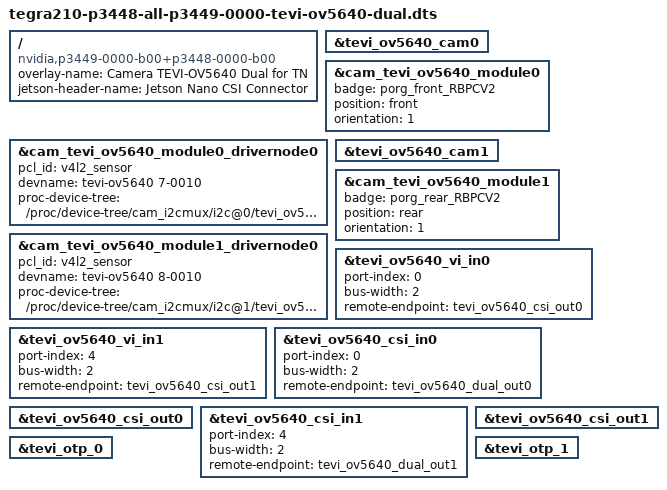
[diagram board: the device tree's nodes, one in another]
// SPDX-License-Identifier: GPL-2.0-only
/*
 * Jetson Device-tree overlay for Camera IMX477 rbpcv3 for t210 single
 * cam connector baseboards
 *
 * Copyright (c) 2021 NVIDIA CORPORATION. All rights reserved.
 *
 */

/dts-v1/;
/plugin/;

/ {
	overlay-name = "Camera TEVI-OV5640 Dual for TN";
	jetson-header-name = "Jetson Nano CSI Connector";
	compatible = "nvidia,p3449-0000-b00+p3448-0000-b00", "nvidia,p3449-0000-b00+p3448-0002-b00";

	/* TEVI-OV5640 dual sensor module */
	fragment@0 {
		target = <&tevi_ov5640_cam0>;
		__overlay__ {
			status = "okay";
		};
	};
	fragment@1 {
		target = <&cam_tevi_ov5640_module0>;
		__overlay__ {
			status = "okay";
			badge = "porg_front_RBPCV2";
			position = "front";
			orientation = "1";
		};
	};
	fragment@2 {
		target = <&cam_tevi_ov5640_module0_drivernode0>;
		__overlay__ {
			status = "okay";
			pcl_id = "v4l2_sensor";
			devname = "tevi-ov5640 7-0010";
			proc-device-tree = "/proc/device-tree/cam_i2cmux/i2c@0/tevi_ov5640_a@3d";
		};
	};
	fragment@3 {
		target = <&tevi_ov5640_cam1>;
		__overlay__ {
			status = "okay";
		};
	};
	fragment@4 {
		target = <&cam_tevi_ov5640_module1>;
		__overlay__ {
			status = "okay";
			badge = "porg_rear_RBPCV2";
			position = "rear";
			orientation = "1";
		};
	};
	fragment@5 {
		target = <&cam_tevi_ov5640_module1_drivernode0>;
		__overlay__ {
			status = "okay";
			pcl_id = "v4l2_sensor";
			devname = "tevi-ov5640 8-0010";
			proc-device-tree = "/proc/device-tree/cam_i2cmux/i2c@1/tevi_ov5640_e@3d";
		};
	};
	fragment@6 {
		target = <&tevi_ov5640_vi_in0>;
		__overlay__ {
			status = "okay";
			port-index = <0>;
			bus-width = <2>;
			remote-endpoint = <&tevi_ov5640_csi_out0>;
		};
	};
	fragment@7 {
		target = <&tevi_ov5640_vi_in1>;
		__overlay__ {
			status = "okay";
			port-index = <4>;
			bus-width = <2>;
			remote-endpoint = <&tevi_ov5640_csi_out1>;
		};
	};
	fragment@8 {
		target = <&tevi_ov5640_csi_in0>;
		__overlay__ {
			status = "okay";
			port-index = <0>;
			bus-width = <2>;
			remote-endpoint = <&tevi_ov5640_dual_out0>;
		};
	};
	fragment@9 {
		target = <&tevi_ov5640_csi_out0>;
		__overlay__ {
			status = "okay";
		};
	};
	fragment@10 {
		target = <&tevi_ov5640_csi_in1>;
		__overlay__ {
			status = "okay";
			port-index = <4>;
			bus-width = <2>;
			remote-endpoint = <&tevi_ov5640_dual_out1>;
		};
	};
	fragment@11 {
		target = <&tevi_ov5640_csi_out1>;
		__overlay__ {
			status = "okay";
		};
	};
	fragment@12 {
		target = <&tevi_otp_0>;
		__overlay__ {
			status = "okay";
		};
	};
	fragment@13 {
		target = <&tevi_otp_1>;
		__overlay__ {
			status = "okay";
		};
	};
};
